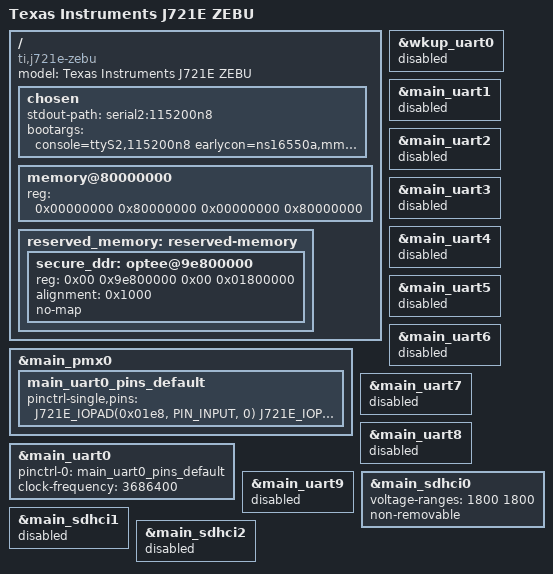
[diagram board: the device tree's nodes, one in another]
// SPDX-License-Identifier: GPL-2.0
/*
 * Copyright (C) 2019 Texas Instruments Incorporated - http://www.ti.com/
 */

/dts-v1/;

#include "k3-j721e.dtsi"

/ {
	compatible =  "ti,j721e-zebu", "ti,j721e";
	model = "Texas Instruments J721E ZEBU";

	chosen {
		stdout-path = "serial2:115200n8";
		bootargs = "console=ttyS2,115200n8 earlycon=ns16550a,mmio32,0x02800000 rdinit=/bin/sh";
	};

	memory@80000000 {
		device_type = "memory";
		/* 2G RAM */
		reg = <0x00000000 0x80000000 0x00000000 0x80000000>;

	};

	reserved_memory: reserved-memory {
		#address-cells = <2>;
		#size-cells = <2>;
		ranges;

		secure_ddr: optee@9e800000 {
			reg = <0x00 0x9e800000 0x00 0x01800000>;
			alignment = <0x1000>;
			no-map;
		};
	};
};

&main_pmx0 {
	main_uart0_pins_default: main_uart0_pins_default {
		pinctrl-single,pins = <
			J721E_IOPAD(0x01e8, PIN_INPUT, 0)  /* UART0_RXD */
			J721E_IOPAD(0x01ec, PIN_OUTPUT, 0) /* UART0_TXD */
			J721E_IOPAD(0x01f0, PIN_INPUT, 0)  /* UART0_CTSn */
			J721E_IOPAD(0x01f4, PIN_OUTPUT, 0) /* UART0_RTSn */
		>;
	};
};

&wkup_uart0 {
	/* Wakeup UART is used by System firmware */
	status = "disabled";
};

&main_uart0 {
	pinctrl-names = "default";
	pinctrl-0 = <&main_uart0_pins_default>;
	clock-frequency = <3686400>;
};

/* The Main 1-9 UARTs do NOT show up in Zebu/QT - Enable them only for testing */
&main_uart1 {
	status = "disabled";
};

&main_uart2 {
	status = "disabled";
};

&main_uart3 {
	status = "disabled";
};

&main_uart4 {
	status = "disabled";
};

&main_uart5 {
	status = "disabled";
};

&main_uart6 {
	status = "disabled";
};

&main_uart7 {
	status = "disabled";
};

&main_uart8 {
	status = "disabled";
};

&main_uart9 {
	status = "disabled";
};

&main_sdhci0 {
	/* eMMC */
	voltage-ranges = <1800 1800>;
	non-removable;
};

&main_sdhci1 {
	/* Unused */
	status = "disabled";
};

&main_sdhci2 {
	/* Unused */
	status = "disabled";
};
